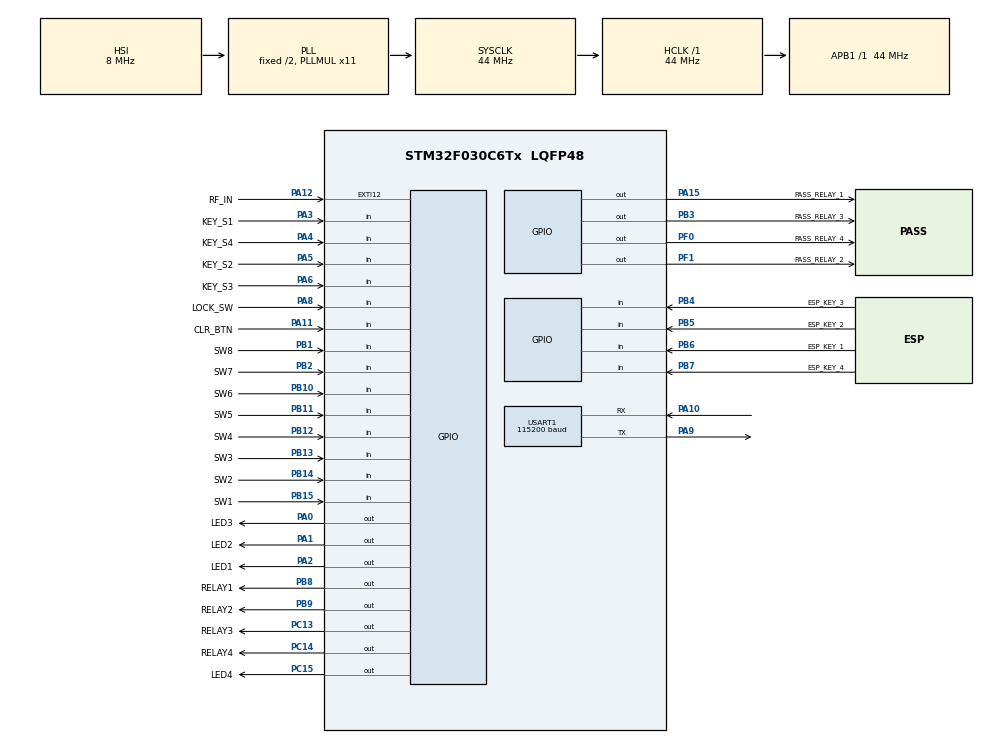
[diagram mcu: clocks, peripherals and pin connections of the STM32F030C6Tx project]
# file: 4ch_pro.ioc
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Mcu.Family=STM32F0
Mcu.Name=STM32F030C6Tx
Mcu.Package=LQFP48
NVIC.EXTI4_15_IRQn=true\:0\:0\:false\:false\:true\:true\:true
PA0.GPIO_Label=LED3
PA0.Signal=GPIO_Output
PA1.GPIO_Label=LED2
PA1.Signal=GPIO_Output
PA10.Mode=Asynchronous
PA10.Signal=USART1_RX
PA11.GPIO_Label=CLR_BTN
PA11.Signal=GPIO_Input
PA12.GPIO_Label=RF_IN
PA12.GPIO_ModeDefaultEXTI=GPIO_MODE_IT_RISING_FALLING
PA12.Signal=GPXTI12
PA15.GPIO_Label=PASS_RELAY_1
PA15.Signal=GPIO_Output
PA2.GPIO_Label=LED1
PA2.Signal=GPIO_Output
PA3.GPIO_Label=KEY_S1
PA3.Signal=GPIO_Input
PA4.GPIO_Label=KEY_S4
PA4.Signal=GPIO_Input
PA5.GPIO_Label=KEY_S2
PA5.Signal=GPIO_Input
PA6.GPIO_Label=KEY_S3
PA6.Signal=GPIO_Input
PA8.GPIO_Label=LOCK_SW
PA8.Signal=GPIO_Input
PA9.Mode=Asynchronous
PA9.Signal=USART1_TX
PB1.GPIO_Label=SW8
PB1.Signal=GPIO_Input
PB10.GPIO_Label=SW6
PB10.Signal=GPIO_Input
PB11.GPIO_Label=SW5
PB11.Signal=GPIO_Input
PB12.GPIO_Label=SW4
PB12.Signal=GPIO_Input
PB13.GPIO_Label=SW3
PB13.Signal=GPIO_Input
PB14.GPIO_Label=SW2
PB14.Signal=GPIO_Input
PB15.GPIO_Label=SW1
PB15.Signal=GPIO_Input
PB2.GPIO_Label=SW7
PB2.Signal=GPIO_Input
PB3.GPIO_Label=PASS_RELAY_3
PB3.Signal=GPIO_Output
PB4.GPIO_Label=ESP_KEY_3
PB4.Signal=GPIO_Input
PB5.GPIO_Label=ESP_KEY_2
PB5.Signal=GPIO_Input
PB6.GPIO_Label=ESP_KEY_1
PB6.Signal=GPIO_Input
PB7.GPIO_Label=ESP_KEY_4
PB7.Signal=GPIO_Input
PB8.GPIO_Label=RELAY1
PB8.Signal=GPIO_Output
PB9.GPIO_Label=RELAY2
PB9.Signal=GPIO_Output
PC13.GPIO_Label=RELAY3
PC13.Signal=GPIO_Output
PC14-OSC32_IN.GPIO_Label=RELAY4
PC14-OSC32_IN.Signal=GPIO_Output
PC15-OSC32_OUT.GPIO_Label=LED4
PC15-OSC32_OUT.Signal=GPIO_Output
PF0-OSC_IN.GPIO_Label=PASS_RELAY_4
PF0-OSC_IN.Signal=GPIO_Output
PF1-OSC_OUT.GPIO_Label=PASS_RELAY_2
PF1-OSC_OUT.Signal=GPIO_Output
ProjectManager.HeapSize=0x200
ProjectManager.StackSize=0x400
ProjectManager.TargetToolchain=MDK-ARM V5.27
RCC.AHBFreq_Value=44000000
RCC.APB1Freq_Value=44000000
RCC.APB1TimFreq_Value=44000000
RCC.HCLKFreq_Value=44000000
RCC.PLLMUL=RCC_PLL_MUL11
RCC.SYSCLKFreq_VALUE=44000000
RCC.SYSCLKSource=RCC_SYSCLKSOURCE_PLLCLK
RCC.Usart1ClockSelection=RCC_USART1CLKSOURCE_SYSCLK
USART1.BaudRate=115200
USART1.VirtualMode-Asynchronous=VM_ASYNC
board=custom

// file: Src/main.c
/* USER CODE BEGIN Header */
/**
  ******************************************************************************
  * @file           : main.c
  * @brief          : Main program body
  ******************************************************************************
  * @attention
  *
  * <h2><center>&copy; Copyright (c) 2019 STMicroelectronics.
  * All rights reserved.</center></h2>
  *
  * This software component is licensed by ST under BSD 3-Clause license,
  * the "License"; You may not use this file except in compliance with the
  * License. You may obtain a copy of the License at:
  *                        opensource.org/licenses/BSD-3-Clause
  *
  ******************************************************************************
  */
/* USER CODE END Header */

#include "main.h"

/* USER CODE BEGIN Includes */
#include "ChControl.h"
/* USER CODE END Includes */

UART_HandleTypeDef huart1;

void SystemClock_Config(void);
static void MX_GPIO_Init(void);
static void MX_USART1_UART_Init(void);

int main(void)
{

  /* MCU Configuration--------------------------------------------------------*/

  /* Reset of all peripherals, Initializes the Flash interface and the Systick. */
  HAL_Init();

  /* Configure the system clock */
  SystemClock_Config();

  /* Initialize all configured peripherals */
  MX_GPIO_Init();
  MX_USART1_UART_Init();

  /* Infinite loop */
  while (1)
  {

  }
}

void SystemClock_Config(void)
{
  RCC_OscInitTypeDef RCC_OscInitStruct = {0};
  RCC_ClkInitTypeDef RCC_ClkInitStruct = {0};
  RCC_PeriphCLKInitTypeDef PeriphClkInit = {0};

  /** Initializes the CPU, AHB and APB busses clocks
  */
  RCC_OscInitStruct.OscillatorType = RCC_OSCILLATORTYPE_HSI;
  RCC_OscInitStruct.HSIState = RCC_HSI_ON;
  RCC_OscInitStruct.HSICalibrationValue = RCC_HSICALIBRATION_DEFAULT;
  RCC_OscInitStruct.PLL.PLLState = RCC_PLL_ON;
  RCC_OscInitStruct.PLL.PLLSource = RCC_PLLSOURCE_HSI;
  RCC_OscInitStruct.PLL.PLLMUL = RCC_PLL_MUL11;
  RCC_OscInitStruct.PLL.PREDIV = RCC_PREDIV_DIV1;
  if (HAL_RCC_OscConfig(&RCC_OscInitStruct) != HAL_OK)
  {
    Error_Handler();
  }
  /** Initializes the CPU, AHB and APB busses clocks
  */
  RCC_ClkInitStruct.ClockType = RCC_CLOCKTYPE_HCLK|RCC_CLOCKTYPE_SYSCLK
                              |RCC_CLOCKTYPE_PCLK1;
  RCC_ClkInitStruct.SYSCLKSource = RCC_SYSCLKSOURCE_PLLCLK;
  RCC_ClkInitStruct.AHBCLKDivider = RCC_SYSCLK_DIV1;
  RCC_ClkInitStruct.APB1CLKDivider = RCC_HCLK_DIV1;

  if (HAL_RCC_ClockConfig(&RCC_ClkInitStruct, FLASH_LATENCY_1) != HAL_OK)
  {
    Error_Handler();
  }
  PeriphClkInit.PeriphClockSelection = RCC_PERIPHCLK_USART1;
  PeriphClkInit.Usart1ClockSelection = RCC_USART1CLKSOURCE_SYSCLK;
  if (HAL_RCCEx_PeriphCLKConfig(&PeriphClkInit) != HAL_OK)
  {
    Error_Handler();
  }
}

static void MX_USART1_UART_Init(void)
{

  huart1.Instance = USART1;
  huart1.Init.BaudRate = 115200;
  huart1.Init.WordLength = UART_WORDLENGTH_8B;
  huart1.Init.StopBits = UART_STOPBITS_1;
  huart1.Init.Parity = UART_PARITY_NONE;
  huart1.Init.Mode = UART_MODE_TX_RX;
  huart1.Init.HwFlowCtl = UART_HWCONTROL_NONE;
  huart1.Init.OverSampling = UART_OVERSAMPLING_16;
  huart1.Init.OneBitSampling = UART_ONE_BIT_SAMPLE_DISABLE;
  huart1.AdvancedInit.AdvFeatureInit = UART_ADVFEATURE_NO_INIT;
  if (HAL_UART_Init(&huart1) != HAL_OK)
  {
    Error_Handler();
  }

}

static void MX_GPIO_Init(void)
{
  GPIO_InitTypeDef GPIO_InitStruct = {0};

  /* GPIO Ports Clock Enable */
  __HAL_RCC_GPIOC_CLK_ENABLE();
  __HAL_RCC_GPIOF_CLK_ENABLE();
  __HAL_RCC_GPIOA_CLK_ENABLE();
  __HAL_RCC_GPIOB_CLK_ENABLE();

  /*Configure GPIO pin Output Level */
  HAL_GPIO_WritePin(GPIOC, RELAY3_Pin|RELAY4_Pin|LED4_Pin, GPIO_PIN_RESET);

  /*Configure GPIO pin Output Level */
  HAL_GPIO_WritePin(GPIOF, PASS_RELAY_4_Pin|PASS_RELAY_2_Pin, GPIO_PIN_RESET);

  /*Configure GPIO pin Output Level */
  HAL_GPIO_WritePin(GPIOA, LED3_Pin|LED2_Pin|LED1_Pin|PASS_RELAY_1_Pin, GPIO_PIN_RESET);

  /*Configure GPIO pin Output Level */
  HAL_GPIO_WritePin(GPIOB, PASS_RELAY_3_Pin|RELAY1_Pin|RELAY2_Pin, GPIO_PIN_RESET);

  /*Configure GPIO pins : RELAY3_Pin RELAY4_Pin LED4_Pin */
  GPIO_InitStruct.Pin = RELAY3_Pin|RELAY4_Pin|LED4_Pin;
  GPIO_InitStruct.Mode = GPIO_MODE_OUTPUT_PP;
  GPIO_InitStruct.Pull = GPIO_NOPULL;
  GPIO_InitStruct.Speed = GPIO_SPEED_FREQ_LOW;
  HAL_GPIO_Init(GPIOC, &GPIO_InitStruct);

  /*Configure GPIO pins : PASS_RELAY_4_Pin PASS_RELAY_2_Pin */
  GPIO_InitStruct.Pin = PASS_RELAY_4_Pin|PASS_RELAY_2_Pin;
  GPIO_InitStruct.Mode = GPIO_MODE_OUTPUT_PP;
  GPIO_InitStruct.Pull = GPIO_NOPULL;
  GPIO_InitStruct.Speed = GPIO_SPEED_FREQ_LOW;
  HAL_GPIO_Init(GPIOF, &GPIO_InitStruct);

  /*Configure GPIO pins : LED3_Pin LED2_Pin LED1_Pin PASS_RELAY_1_Pin */
  GPIO_InitStruct.Pin = LED3_Pin|LED2_Pin|LED1_Pin|PASS_RELAY_1_Pin;
  GPIO_InitStruct.Mode = GPIO_MODE_OUTPUT_PP;
  GPIO_InitStruct.Pull = GPIO_NOPULL;
  GPIO_InitStruct.Speed = GPIO_SPEED_FREQ_LOW;
  HAL_GPIO_Init(GPIOA, &GPIO_InitStruct);

  /*Configure GPIO pins : KEY_S1_Pin KEY_S4_Pin KEY_S2_Pin KEY_S3_Pin
                           LOCK_SW_Pin CLR_BTN_Pin */
  GPIO_InitStruct.Pin = KEY_S1_Pin|KEY_S4_Pin|KEY_S2_Pin|KEY_S3_Pin
                          |LOCK_SW_Pin|CLR_BTN_Pin;
  GPIO_InitStruct.Mode = GPIO_MODE_INPUT;
  GPIO_InitStruct.Pull = GPIO_NOPULL;
  HAL_GPIO_Init(GPIOA, &GPIO_InitStruct);

  /*Configure GPIO pins : SW8_Pin SW7_Pin SW6_Pin SW5_Pin
                           SW4_Pin SW3_Pin SW2_Pin SW1_Pin
                           ESP_KEY_3_Pin ESP_KEY_2_Pin ESP_KEY_1_Pin ESP_KEY_4_Pin */
  GPIO_InitStruct.Pin = SW8_Pin|SW7_Pin|SW6_Pin|SW5_Pin
                          |SW4_Pin|SW3_Pin|SW2_Pin|SW1_Pin
                          |ESP_KEY_3_Pin|ESP_KEY_2_Pin|ESP_KEY_1_Pin|ESP_KEY_4_Pin;
  GPIO_InitStruct.Mode = GPIO_MODE_INPUT;
  GPIO_InitStruct.Pull = GPIO_NOPULL;
  HAL_GPIO_Init(GPIOB, &GPIO_InitStruct);

  /*Configure GPIO pin : RF_IN_Pin */
  GPIO_InitStruct.Pin = RF_IN_Pin;
  GPIO_InitStruct.Mode = GPIO_MODE_IT_RISING_FALLING;
  GPIO_InitStruct.Pull = GPIO_NOPULL;
  HAL_GPIO_Init(RF_IN_GPIO_Port, &GPIO_InitStruct);

  /*Configure GPIO pins : PASS_RELAY_3_Pin RELAY1_Pin RELAY2_Pin */
  GPIO_InitStruct.Pin = PASS_RELAY_3_Pin|RELAY1_Pin|RELAY2_Pin;
  GPIO_InitStruct.Mode = GPIO_MODE_OUTPUT_PP;
  GPIO_InitStruct.Pull = GPIO_NOPULL;
  GPIO_InitStruct.Speed = GPIO_SPEED_FREQ_LOW;
  HAL_GPIO_Init(GPIOB, &GPIO_InitStruct);

  /* EXTI interrupt init*/
  HAL_NVIC_SetPriority(EXTI4_15_IRQn, 0, 0);
  HAL_NVIC_EnableIRQ(EXTI4_15_IRQn);

}

void Error_Handler(void)
{
}

/************************ (C) COPYRIGHT STMicroelectronics *****END OF FILE****/
